VERSION ""

NS_ :

BS_:

BU_: XXX

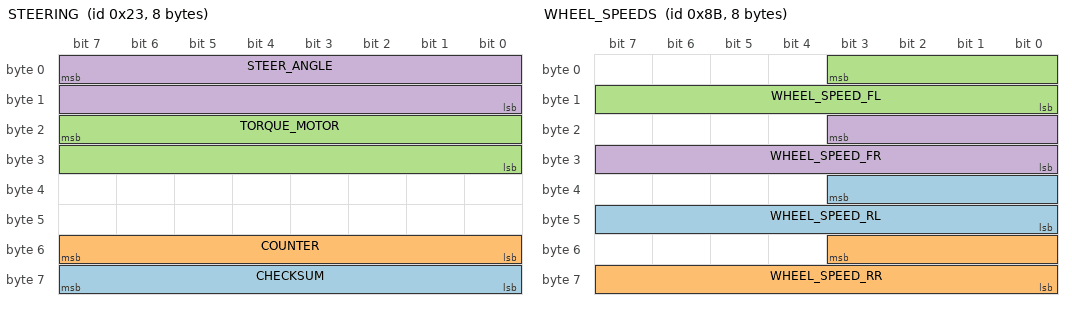
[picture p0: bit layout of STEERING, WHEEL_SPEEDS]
BO_ 35 STEERING: 8 XXX
 SG_ CHECKSUM : 63|8@0+ (1,0) [0|65535] "" XXX
 SG_ COUNTER : 55|8@0+ (1,0) [0|1] "" XXX
 SG_ TORQUE_MOTOR : 23|16@0+ (1,-4096) [0|65535] "" XXX
 SG_ STEER_ANGLE : 7|16@0+ (0.5,-2048) [0|65535] "degs" XXX

BO_ 139 WHEEL_SPEEDS: 8 XXX
 SG_ WHEEL_SPEED_RL : 35|12@0+ (1,0) [0|1] "" XXX
 SG_ WHEEL_SPEED_RR : 51|12@0+ (1,0) [0|1] "" XXX
 SG_ WHEEL_SPEED_FL : 3|12@0+ (1,0) [0|1] "" XXX
 SG_ WHEEL_SPEED_FR : 19|12@0+ (1,0) [0|1] "" XXX

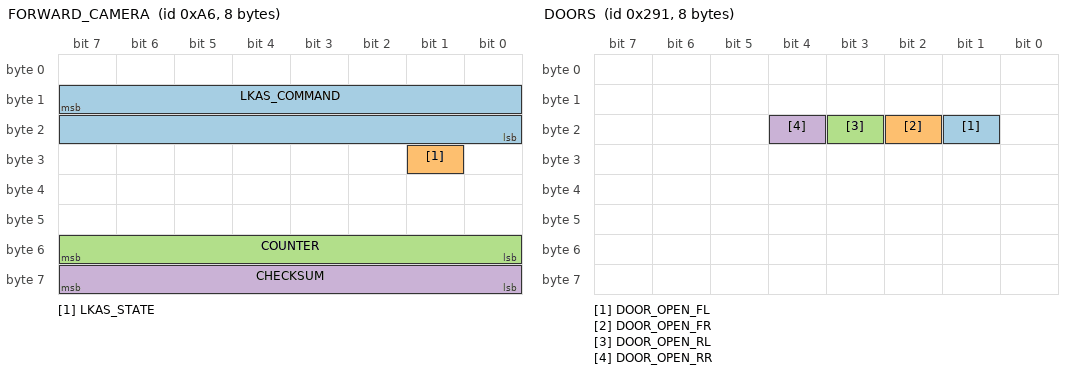
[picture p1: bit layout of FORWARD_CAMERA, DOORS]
BO_ 166 FORWARD_CAMERA: 8 XXX
 SG_ LKAS_COMMAND : 15|16@0+ (1,-1024) [0|4095] "" XXX
 SG_ LKAS_STATE : 25|1@0+ (1,0) [0|1] "" XXX
 SG_ COUNTER : 55|8@0+ (1,0) [0|1] "" XXX
 SG_ CHECKSUM : 63|8@0+ (1,0) [0|1] "" XXX

BO_ 311 SEATBELT_STATUS: 8 XXX
 SG_ SEATBELT_DRIVER_UNLATCHED : 60|5@0+ (1,0) [0|31] "" XXX

BO_ 792 STEERING_LEVERS: 8 XXX
 SG_ TURN_SIGNALS : 0|2@1+ (1,0) [0|3] "" XXX
 SG_ HIGH_BEAM_FLASH : 2|2@1+ (1,0) [0|3] "" XXX

BO_ 133 GEAR: 8 XXX
 SG_ PRNDL : 5|14@0+ (1,0) [0|16383] "" XXX

BO_ 657 DOORS: 8 XXX
 SG_ DOOR_OPEN_FL : 17|1@0+ (1,0) [0|1] "" XXX
 SG_ DOOR_OPEN_FR : 18|1@1+ (1,0) [0|3] "" XXX
 SG_ DOOR_OPEN_RL : 19|1@0+ (1,0) [0|1] "" XXX
 SG_ DOOR_OPEN_RR : 20|1@0+ (1,0) [0|1] "" XXX

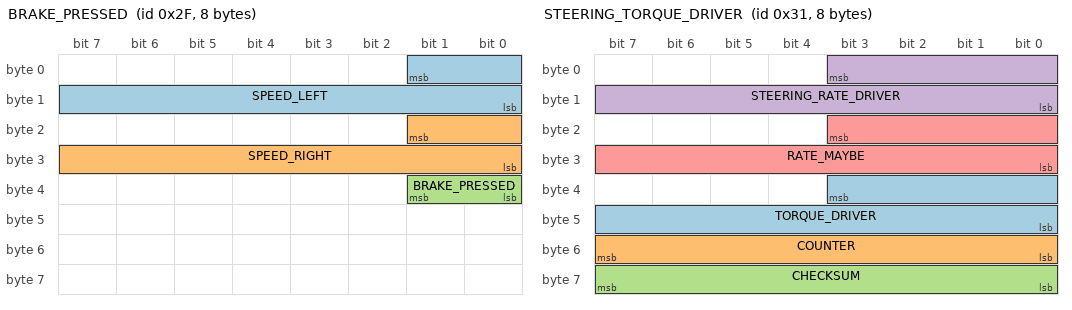
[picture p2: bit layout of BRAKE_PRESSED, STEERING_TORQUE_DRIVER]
BO_ 47 BRAKE_PRESSED: 8 XXX
 SG_ SPEED_LEFT : 1|10@0+ (1,0) [0|8191] "" XXX
 SG_ SPEED_RIGHT : 17|10@0+ (1,0) [0|3] "" XXX
 SG_ BRAKE_PRESSED : 32|2@1+ (1,0) [0|3] "" XXX

BO_ 37 GAS_PEDAL_NO: 8 XXX
 SG_ ACCL_134 : 36|13@0+ (1,0) [0|8191] "" XXX

BO_ 121 BRAKE_3: 8 XXX
 SG_ BRAKE_PRESSURE : 3|12@0+ (1,0) [0|255] "" XXX
 SG_ GAS_PEDAL : 34|11@0+ (1,0) [0|3] "" XXX

BO_ 53 THROTTLE_MAYBE_NO: 8 XXX
 SG_ GAS_PEDAL_MAYBE : 3|12@0+ (1,0) [0|7] "" XXX

BO_ 49 STEERING_TORQUE_DRIVER: 8 XXX
 SG_ TORQUE_DRIVER : 35|12@0+ (1,-1024) [-1024|1024] "" XXX
 SG_ COUNTER : 55|8@0+ (1,0) [0|1] "" XXX
 SG_ CHECKSUM : 63|8@0+ (1,0) [0|1] "" XXX
 SG_ STEERING_RATE_DRIVER : 3|12@0+ (1,0) [0|32767] "" XXX
 SG_ RATE_MAYBE : 19|12@0+ (1,0) [0|1] "" XXX

BO_ 221 CENTER_STACK: 8 XXX
 SG_ TRAC_OFF : 54|1@0+ (1,0) [0|1] "" XXX

BO_ 153 ACC_STATUS: 8 XXX
 SG_ ACC_STATUS : 21|2@0+ (1,0) [0|3] "" XXX

CM_ SG_ 35 STEER_ANGLE "540 deg total negative values indicate right turn, positive values indicate left turn";
CM_ SG_ 166 LKAS_STATE "appears to be the lkas ready indicator";
CM_ SG_ 792 TURN_SIGNALS "RIGHT IS 2 LEFT IS 1";
CM_ SG_ 792 HIGH_BEAM_FLASH "4 IS HIGH BEAMS ON 8 IS FLASH";
